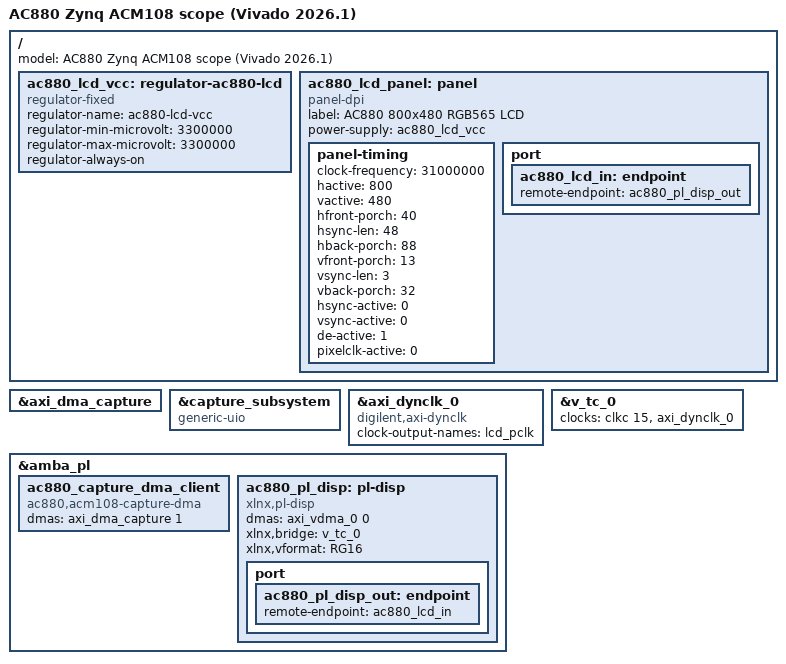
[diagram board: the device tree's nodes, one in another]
/* AC880 + ACM108 scope feature layer, generated from the Vivado 2026.1 XSA. */

#include "dt-bindings/gpio/gpio.h"

/* The AXI DMA node is generated by PetaLinux from the XSA.  Keep its
 * xlnx,axi-dma-7.1 compatible data and HP1 address mapping intact. */
&axi_dma_capture {
        status = "okay";
};

/* The custom AXI-Lite register block has no kernel-specific protocol.  Bind
 * it to uio_pdrv_genirq so bring-up software can mmap 0x43C20000 safely. */
&capture_subsystem {
        compatible = "generic-uio";
        status = "okay";
};

/* The PL pixel clock is the Digilent AXI dynamic-clock output.  The
 * generated XSA describes this IP as a fixed clock, which leaves its MMCM
 * registers at reset and holds rgb2lcd in video reset.  Expose the real
 * clock provider so the Xilinx VTC bridge can call clk_set_rate() during
 * modeset. */
&axi_dynclk_0 {
        #clock-cells = <0>;
        compatible = "digilent,axi-dynclk";
        clock-output-names = "lcd_pclk";
        status = "okay";
};

&amba_pl {
        ac880_capture_dma_client {
                compatible = "ac880,acm108-capture-dma";
                /* AXI DMA channel 1 is the S2MM receive channel. */
                dmas = <&axi_dma_capture 1>;
                dma-names = "rx";
                status = "okay";
        };

        /*
         * Xilinx PL Display DRM CRTC.  Channel 0 of the AXI VDMA is the
         * memory-to-stream (MM2S) display channel.  The downstream
         * rgb2lcd RTL is not a Linux device, so the graph endpoint is tied
         * to the descriptive DPI panel node below.
         */
        ac880_pl_disp: pl-disp {
                compatible = "xlnx,pl-disp";
                dmas = <&axi_vdma_0 0>;
                dma-names = "dma0";
                xlnx,bridge = <&v_tc_0>;
                /* DRM_FORMAT_RGB565 (little-endian) FourCC. */
                xlnx,vformat = "RG16";

                port {
                        ac880_pl_disp_out: endpoint {
                                remote-endpoint = <&ac880_lcd_in>;
                        };
                };
        };
};

/ {
        model = "AC880 Zynq ACM108 scope (Vivado 2026.1)";

        /* The LCD rail is board-powered; this fixed regulator models the
         * always-on supply required by the generic panel-dpi binding. */
        ac880_lcd_vcc: regulator-ac880-lcd {
                compatible = "regulator-fixed";
                regulator-name = "ac880-lcd-vcc";
                regulator-min-microvolt = <3300000>;
                regulator-max-microvolt = <3300000>;
                regulator-always-on;
        };

        /* Fixed mode description for the parallel RGB LCD. */
        ac880_lcd_panel: panel {
                compatible = "panel-dpi";
                label = "AC880 800x480 RGB565 LCD";
                power-supply = <&ac880_lcd_vcc>;
                panel-timing {
                        /* AC880 tutorial timing: 31 MHz pixel clock. */
                        clock-frequency = <31000000>;
                        hactive = <800>;
                        vactive = <480>;
                        hfront-porch = <40>;
                        hsync-len = <48>;
                        hback-porch = <88>;
                        vfront-porch = <13>;
                        vsync-len = <3>;
                        vback-porch = <32>;
                        /* AC880 TFT timing: HS/VS/PCLK are low-active. */
                        hsync-active = <0>;
                        vsync-active = <0>;
                        de-active = <1>;
                        pixelclk-active = <0>;
                };

                port {
                        ac880_lcd_in: endpoint {
                                remote-endpoint = <&ac880_pl_disp_out>;
                        };
                };
        };
};

/* Match the current xlnx,bridge-v-tc binding order while retaining the
 * generated VTC clocks and letting the DRM bridge set timing at modeset. */
&v_tc_0 {
        clock-names = "s_axi_aclk", "clk";
        clocks = <&clkc 15>, <&axi_dynclk_0>;
        status = "okay";
};
